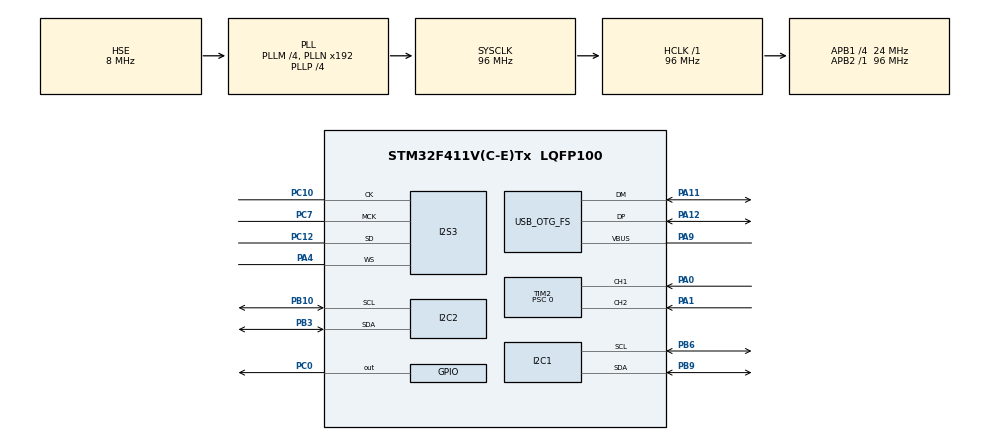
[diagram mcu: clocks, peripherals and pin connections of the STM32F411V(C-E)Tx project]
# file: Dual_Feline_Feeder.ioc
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Dma.Request0=SPI3_TX
Dma.SPI3_TX.0.Direction=DMA_MEMORY_TO_PERIPH
Dma.SPI3_TX.0.FIFOMode=DMA_FIFOMODE_ENABLE
Dma.SPI3_TX.0.FIFOThreshold=DMA_FIFO_THRESHOLD_FULL
Dma.SPI3_TX.0.Instance=DMA1_Stream5
Dma.SPI3_TX.0.MemBurst=DMA_MBURST_SINGLE
Dma.SPI3_TX.0.MemDataAlignment=DMA_MDATAALIGN_HALFWORD
Dma.SPI3_TX.0.MemInc=DMA_MINC_ENABLE
Dma.SPI3_TX.0.Mode=DMA_CIRCULAR
Dma.SPI3_TX.0.PeriphBurst=DMA_PBURST_SINGLE
Dma.SPI3_TX.0.PeriphDataAlignment=DMA_PDATAALIGN_HALFWORD
Dma.SPI3_TX.0.PeriphInc=DMA_PINC_DISABLE
Dma.SPI3_TX.0.Priority=DMA_PRIORITY_LOW
FATFS._USE_LFN=1
I2S3.AudioFreq=I2S_AUDIOFREQ_44K
I2S3.ErrorAudioFreq=1.45 %
I2S3.FullDuplexMode=I2S_FULLDUPLEXMODE_DISABLE
I2S3.Instance=SPI$Index
I2S3.RealAudioFreq=44.642 KHz
I2S3.VirtualMode=I2S_MODE_MASTER
Mcu.Family=STM32F4
Mcu.Name=STM32F411V(C-E)Tx
Mcu.Package=LQFP100
NVIC.DMA1_Stream5_IRQn=true\:0\:0\:false\:false\:true\:false\:true\:true
NVIC.OTG_FS_IRQn=true\:0\:0\:false\:false\:true\:false\:true\:true
NVIC.PriorityGroup=NVIC_PRIORITYGROUP_0
NVIC.TIM2_IRQn=true\:0\:0\:false\:false\:true\:true\:true\:true
PA0-WKUP.GPIO_PuPd=GPIO_PULLUP
PA0-WKUP.Signal=S_TIM2_CH1_ETR
PA1.GPIO_PuPd=GPIO_PULLUP
PA1.Signal=S_TIM2_CH2
PA11.Mode=Host_Only
PA11.Signal=USB_OTG_FS_DM
PA12.Mode=Host_Only
PA12.Signal=USB_OTG_FS_DP
PA4.Mode=Half_Duplex_Master
PA4.Signal=I2S3_WS
PA9.Mode=Activate_VBUS
PA9.Signal=USB_OTG_FS_VBUS
PB10.Mode=I2C
PB10.Signal=I2C2_SCL
PB3.Mode=I2C
PB3.Signal=I2C2_SDA
PB6.Mode=I2C
PB6.Signal=I2C1_SCL
PB9.Mode=I2C
PB9.Signal=I2C1_SDA
PC0.PinState=GPIO_PIN_RESET
PC0.Signal=GPIO_Output
PC10.Mode=Half_Duplex_Master
PC10.Signal=I2S3_CK
PC12.Mode=Half_Duplex_Master
PC12.Signal=I2S3_SD
PC7.Mode=Master_Clock_Activated
PC7.Signal=I2S3_MCK
PH0\ -\ OSC_IN.Mode=HSE-External-Oscillator
PH0\ -\ OSC_IN.Signal=RCC_OSC_IN
PH1\ -\ OSC_OUT.Mode=HSE-External-Oscillator
PH1\ -\ OSC_OUT.Signal=RCC_OSC_OUT
ProjectManager.HeapSize=0x200
ProjectManager.StackSize=0x400
ProjectManager.TargetToolchain=STM32CubeIDE
RCC.48MHZClocksFreq_Value=48000000
RCC.AHBFreq_Value=96000000
RCC.APB1CLKDivider=RCC_HCLK_DIV4
RCC.APB1Freq_Value=24000000
RCC.APB1TimFreq_Value=48000000
RCC.APB2Freq_Value=96000000
RCC.APB2TimFreq_Value=96000000
RCC.CortexFreq_Value=96000000
RCC.HCLKFreq_Value=96000000
RCC.HSE_VALUE=8000000
RCC.HSI_VALUE=16000000
RCC.LSE_VALUE=32768
RCC.PLLI2SM=5
RCC.PLLI2SN=200
RCC.PLLM=4
RCC.PLLP=RCC_PLLP_DIV4
RCC.PLLQ=8
RCC.RCC_RTC_Clock_Source=RCC_RTCCLKSOURCE_HSE_DIV8
RCC.RCC_RTC_Clock_Source_FROM_HSE=RCC_RTCCLKSOURCE_HSE_DIV8
RCC.SYSCLKFreq_VALUE=96000000
RCC.SYSCLKSource=RCC_SYSCLKSOURCE_PLLCLK
RCC.VCOOutputFreq_Value=384000000
SH.S_TIM2_CH1_ETR.0=TIM2_CH1,Encoder_Interface
SH.S_TIM2_CH2.0=TIM2_CH2,Encoder_Interface
TIM2.ClockDivision=TIM_CLOCKDIVISION_DIV1
TIM2.EncoderMode=TIM_ENCODERMODE_TI1
TIM2.IC1Polarity=TIM_ICPOLARITY_RISING
TIM2.IC1Prescaler=TIM_ICPSC_DIV1
TIM2.IC2Polarity=TIM_ICPOLARITY_RISING
TIM2.IC2Prescaler=TIM_ICPSC_DIV1
TIM2.Prescaler=0
USB_HOST.BSP.number=1
USB_HOST.USBH_HandleTypeDef=hUsbHostFS
USB_HOST.VirtualModeFS=Msc
USB_HOST0.BSP.STBoard=false
USB_HOST0.BSP.api=Unknown
USB_HOST0.BSP.condition=SW_VBUS_DRIVE_MSC_FS \= false
USB_HOST0.BSP.instance=PC0
USB_HOST0.BSP.ip=GPIO
USB_HOST0.BSP.mode=Output
USB_HOST0.BSP.name=Drive_VBUS_FS
USB_HOST0.BSP.solution=PC0
USB_OTG_FS.VirtualMode=Host_Only
USB_OTG_FS.phy_itface=HCD_PHY_EMBEDDED
VP_FATFS_VS_USB.Mode=USB
VP_USB_HOST_VS_USB_HOST_MSC_FS.Mode=MSC_FS
board=STM32F411E-DISCO

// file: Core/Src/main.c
/* USER CODE BEGIN Header */
/**
  ******************************************************************************
  * @file           : main.c
  * @brief          : Main program body
  ******************************************************************************
  * @attention
  *
  * Copyright (c) 2023 STMicroelectronics.
  * All rights reserved.
  *
  * This software is licensed under terms that can be found in the LICENSE file
  * in the root directory of this software component.
  * If no LICENSE file comes with this software, it is provided AS-IS.
  *
  ******************************************************************************
  */
/* USER CODE END Header */
#include "main.h"
#include "dma.h"
#include "fatfs.h"
#include "i2c.h"
#include "i2s.h"
#include "tim.h"
#include "usb_host.h"
#include "gpio.h"

/* USER CODE BEGIN Includes */
#include <App.h>
/* USER CODE END Includes */

void SystemClock_Config(void);
void MX_USB_HOST_Process(void);

int main(void)
{

  /* MCU Configuration--------------------------------------------------------*/

  /* Reset of all peripherals, Initializes the Flash interface and the Systick. */
  HAL_Init();

  /* Configure the system clock */
  SystemClock_Config();

  /* Initialize all configured peripherals */
  MX_GPIO_Init();
  MX_DMA_Init();
  MX_I2C1_Init();
  MX_I2S3_Init();
  MX_FATFS_Init();
  MX_USB_HOST_Init();
  MX_I2C2_Init();
  MX_TIM2_Init();

  /* Infinite loop */
  while (1)
  {
    MX_USB_HOST_Process();

    /* USER CODE BEGIN 3 */

    app_main();
  }
  /* USER CODE END 3 */
}

void SystemClock_Config(void)
{
  RCC_OscInitTypeDef RCC_OscInitStruct = {0};
  RCC_ClkInitTypeDef RCC_ClkInitStruct = {0};

  /** Configure the main internal regulator output voltage
  */
  __HAL_RCC_PWR_CLK_ENABLE();
  __HAL_PWR_VOLTAGESCALING_CONFIG(PWR_REGULATOR_VOLTAGE_SCALE1);

  /** Initializes the RCC Oscillators according to the specified parameters
  * in the RCC_OscInitTypeDef structure.
  */
  RCC_OscInitStruct.OscillatorType = RCC_OSCILLATORTYPE_HSE;
  RCC_OscInitStruct.HSEState = RCC_HSE_ON;
  RCC_OscInitStruct.PLL.PLLState = RCC_PLL_ON;
  RCC_OscInitStruct.PLL.PLLSource = RCC_PLLSOURCE_HSE;
  RCC_OscInitStruct.PLL.PLLM = 4;
  RCC_OscInitStruct.PLL.PLLN = 192;
  RCC_OscInitStruct.PLL.PLLP = RCC_PLLP_DIV4;
  RCC_OscInitStruct.PLL.PLLQ = 8;
  if (HAL_RCC_OscConfig(&RCC_OscInitStruct) != HAL_OK)
  {
    Error_Handler();
  }

  /** Initializes the CPU, AHB and APB buses clocks
  */
  RCC_ClkInitStruct.ClockType = RCC_CLOCKTYPE_HCLK|RCC_CLOCKTYPE_SYSCLK
                              |RCC_CLOCKTYPE_PCLK1|RCC_CLOCKTYPE_PCLK2;
  RCC_ClkInitStruct.SYSCLKSource = RCC_SYSCLKSOURCE_PLLCLK;
  RCC_ClkInitStruct.AHBCLKDivider = RCC_SYSCLK_DIV1;
  RCC_ClkInitStruct.APB1CLKDivider = RCC_HCLK_DIV4;
  RCC_ClkInitStruct.APB2CLKDivider = RCC_HCLK_DIV1;

  if (HAL_RCC_ClockConfig(&RCC_ClkInitStruct, FLASH_LATENCY_3) != HAL_OK)
  {
    Error_Handler();
  }
}

void Error_Handler(void)
{
  __disable_irq();
  while (1)
  {
  }
}
